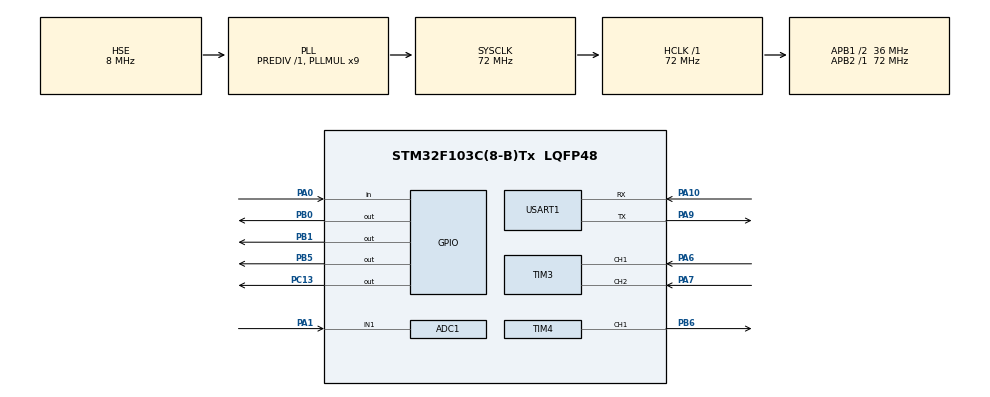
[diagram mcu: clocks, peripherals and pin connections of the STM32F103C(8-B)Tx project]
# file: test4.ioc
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ADC1.Channel-0\#ChannelRegularConversion=ADC_CHANNEL_1
ADC1.ContinuousConvMode=ENABLE
ADC1.NbrOfConversionFlag=1
ADC1.Rank-0\#ChannelRegularConversion=1
ADC1.SamplingTime-0\#ChannelRegularConversion=ADC_SAMPLETIME_71CYCLES_5
ADC1.master=1
FREERTOS.Tasks01=defaultTask,24,128,StartDefaultTask,Default,NULL,Dynamic,NULL,NULL
FREERTOS.configCHECK_FOR_STACK_OVERFLOW=2
FREERTOS.configTOTAL_HEAP_SIZE=8192
Mcu.Family=STM32F1
Mcu.Name=STM32F103C(8-B)Tx
Mcu.Package=LQFP48
NVIC.PriorityGroup=NVIC_PRIORITYGROUP_4
NVIC.TIM1_UP_IRQn=true\:15\:0\:false\:false\:true\:false\:false\:true\:true
NVIC.TimeBase=TIM1_UP_IRQn
NVIC.TimeBaseIP=TIM1
PA0-WKUP.GPIO_PuPd=GPIO_PULLUP
PA0-WKUP.Signal=GPIO_Input
PA1.Signal=ADCx_IN1
PA10.Mode=Asynchronous
PA10.Signal=USART1_RX
PA13.Mode=Serial_Wire
PA13.Signal=SYS_JTMS-SWDIO
PA14.Mode=Serial_Wire
PA14.Signal=SYS_JTCK-SWCLK
PA6.Signal=S_TIM3_CH1
PA7.Signal=S_TIM3_CH2
PA9.Mode=Asynchronous
PA9.Signal=USART1_TX
PB0.Signal=GPIO_Output
PB1.Signal=GPIO_Output
PB5.PinState=GPIO_PIN_SET
PB5.Signal=GPIO_Output
PB6.Signal=S_TIM4_CH1
PC13-TAMPER-RTC.PinState=GPIO_PIN_SET
PC13-TAMPER-RTC.Signal=GPIO_Output
PD0-OSC_IN.Mode=HSE-External-Oscillator
PD0-OSC_IN.Signal=RCC_OSC_IN
PD1-OSC_OUT.Mode=HSE-External-Oscillator
PD1-OSC_OUT.Signal=RCC_OSC_OUT
ProjectManager.HeapSize=0x200
ProjectManager.StackSize=0x400
ProjectManager.TargetToolchain=CMake
RCC.ADCPresc=RCC_ADCPCLK2_DIV6
RCC.AHBFreq_Value=72000000
RCC.APB1CLKDivider=RCC_HCLK_DIV2
RCC.APB1Freq_Value=36000000
RCC.APB1TimFreq_Value=72000000
RCC.APB2Freq_Value=72000000
RCC.APB2TimFreq_Value=72000000
RCC.HCLKFreq_Value=72000000
RCC.PLLMUL=RCC_PLL_MUL9
RCC.PLLSourceVirtual=RCC_PLLSOURCE_HSE
RCC.SYSCLKFreq_VALUE=72000000
RCC.SYSCLKSource=RCC_SYSCLKSOURCE_PLLCLK
RCC.USBFreq_Value=72000000
SH.ADCx_IN1.0=ADC1_IN1,IN1
SH.S_TIM3_CH1.0=TIM3_CH1,Encoder_Interface
SH.S_TIM3_CH2.0=TIM3_CH2,Encoder_Interface
SH.S_TIM4_CH1.0=TIM4_CH1,PWM Generation1 CH1
TIM3.EncoderMode=TIM_ENCODERMODE_TI12
TIM4.Channel-PWM\ Generation1\ CH1=TIM_CHANNEL_1
TIM4.Period=3599
TIM4.Prescaler=0
USART1.VirtualMode=VM_ASYNC
VP_FREERTOS_VS_CMSIS_V2.Mode=CMSIS_V2
VP_SYS_VS_tim1.Mode=TIM1
board=custom

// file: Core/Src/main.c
/* USER CODE BEGIN Header */
/**
  ******************************************************************************
  * @file           : main.c
  * @brief          : Main program body
  ******************************************************************************
  * @attention
  *
  * Copyright (c) 2026 STMicroelectronics.
  * All rights reserved.
  *
  * This software is licensed under terms that can be found in the LICENSE file
  * in the root directory of this software component.
  * If no LICENSE file comes with this software, it is provided AS-IS.
  *
  ******************************************************************************
  */
/* USER CODE END Header */
#include "main.h"
#include "cmsis_os.h"
#include "adc.h"
#include "tim.h"
#include "usart.h"
#include "gpio.h"

/* USER CODE BEGIN Includes */
#include "app.h"
/* USER CODE END Includes */

void SystemClock_Config(void);
void MX_FREERTOS_Init(void);

int main(void)
{

  /* MCU Configuration--------------------------------------------------------*/

  /* Reset of all peripherals, Initializes the Flash interface and the Systick. */
  HAL_Init();

  /* Configure the system clock */
  SystemClock_Config();

  /* Initialize all configured peripherals */
  MX_GPIO_Init();
  MX_ADC1_Init();
  MX_TIM3_Init();
  MX_TIM4_Init();
  MX_USART1_UART_Init();
  /* USER CODE BEGIN 2 */
  /* 启动外设：编码器(TIM3) / PWM(TIM4) / ADC 旋钮 —— 必须在调度器启动前完成 */
  app_peripherals_init();
  /* USER CODE END 2 */

  /* Init scheduler */
  osKernelInitialize();  /* Call init function for freertos objects (in cmsis_os2.c) */
  MX_FREERTOS_Init();

  /* Start scheduler */
  osKernelStart();

  /* We should never get here as control is now taken by the scheduler */

  /* Infinite loop */
  while (1)
  {

  }
}

void SystemClock_Config(void)
{
  RCC_OscInitTypeDef RCC_OscInitStruct = {0};
  RCC_ClkInitTypeDef RCC_ClkInitStruct = {0};
  RCC_PeriphCLKInitTypeDef PeriphClkInit = {0};

  /** Initializes the RCC Oscillators according to the specified parameters
  * in the RCC_OscInitTypeDef structure.
  */
  RCC_OscInitStruct.OscillatorType = RCC_OSCILLATORTYPE_HSE;
  RCC_OscInitStruct.HSEState = RCC_HSE_ON;
  RCC_OscInitStruct.HSEPredivValue = RCC_HSE_PREDIV_DIV1;
  RCC_OscInitStruct.HSIState = RCC_HSI_ON;
  RCC_OscInitStruct.PLL.PLLState = RCC_PLL_ON;
  RCC_OscInitStruct.PLL.PLLSource = RCC_PLLSOURCE_HSE;
  RCC_OscInitStruct.PLL.PLLMUL = RCC_PLL_MUL9;
  if (HAL_RCC_OscConfig(&RCC_OscInitStruct) != HAL_OK)
  {
    Error_Handler();
  }

  /** Initializes the CPU, AHB and APB buses clocks
  */
  RCC_ClkInitStruct.ClockType = RCC_CLOCKTYPE_HCLK|RCC_CLOCKTYPE_SYSCLK
                              |RCC_CLOCKTYPE_PCLK1|RCC_CLOCKTYPE_PCLK2;
  RCC_ClkInitStruct.SYSCLKSource = RCC_SYSCLKSOURCE_PLLCLK;
  RCC_ClkInitStruct.AHBCLKDivider = RCC_SYSCLK_DIV1;
  RCC_ClkInitStruct.APB1CLKDivider = RCC_HCLK_DIV2;
  RCC_ClkInitStruct.APB2CLKDivider = RCC_HCLK_DIV1;

  if (HAL_RCC_ClockConfig(&RCC_ClkInitStruct, FLASH_LATENCY_2) != HAL_OK)
  {
    Error_Handler();
  }
  PeriphClkInit.PeriphClockSelection = RCC_PERIPHCLK_ADC;
  PeriphClkInit.AdcClockSelection = RCC_ADCPCLK2_DIV6;
  if (HAL_RCCEx_PeriphCLKConfig(&PeriphClkInit) != HAL_OK)
  {
    Error_Handler();
  }
}

void HAL_TIM_PeriodElapsedCallback(TIM_HandleTypeDef *htim)
{
  if (htim->Instance == TIM1)
  {
    HAL_IncTick();
  }
}

void Error_Handler(void)
{
  __disable_irq();
  while (1)
  {
  }
}

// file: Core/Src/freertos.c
/* USER CODE BEGIN Header */
/**
  ******************************************************************************
  * File Name          : freertos.c
  * Description        : Code for freertos applications
  ******************************************************************************
  * @attention
  *
  * Copyright (c) 2026 STMicroelectronics.
  * All rights reserved.
  *
  * This software is licensed under terms that can be found in the LICENSE file
  * in the root directory of this software component.
  * If no LICENSE file comes with this software, it is provided AS-IS.
  *
  ******************************************************************************
  */
/* USER CODE END Header */

#include "FreeRTOS.h"
#include "task.h"
#include "main.h"
#include "cmsis_os.h"

/* USER CODE BEGIN Includes */
#include "app.h"
/* USER CODE END Includes */

/* Definitions for defaultTask */
osThreadId_t defaultTaskHandle;
const osThreadAttr_t defaultTask_attributes = {
  .name = "defaultTask",
  .stack_size = 128 * 4,
  .priority = (osPriority_t) osPriorityNormal,
};

void StartDefaultTask(void *argument);

void MX_FREERTOS_Init(void); /* (MISRA C 2004 rule 8.1) */

/* Hook prototypes */
void vApplicationStackOverflowHook(xTaskHandle xTask, signed char *pcTaskName);

/* USER CODE BEGIN 4 */
void vApplicationStackOverflowHook(xTaskHandle xTask, signed char *pcTaskName)
{
   /* Run time stack overflow checking is performed if
   configCHECK_FOR_STACK_OVERFLOW is defined to 1 or 2. This hook function is
   called if a stack overflow is detected. */
}
/* USER CODE END 4 */

void MX_FREERTOS_Init(void) {

  /* USER CODE BEGIN RTOS_QUEUES */
  /* 创建队列(旋钮百分比)与互斥锁(遥测/串口) */
  app_rtos_objects_init();
  /* USER CODE END RTOS_QUEUES */

  /* Create the thread(s) */
  /* creation of defaultTask */
  defaultTaskHandle = osThreadNew(StartDefaultTask, NULL, &defaultTask_attributes);

  /* USER CODE BEGIN RTOS_THREADS */
  /* 创建 4 个应用任务：控制环 / 旋钮 / VOFA+ / 按键 */
  app_rtos_tasks_create();
  /* USER CODE END RTOS_THREADS */

}

void StartDefaultTask(void *argument)
{
  /* USER CODE BEGIN StartDefaultTask */
  /* 本工程把 defaultTask 当作心跳灯任务用（定速闪1次 / 定位闪2次） */
  led_task(argument);
  /* USER CODE END StartDefaultTask */
}
